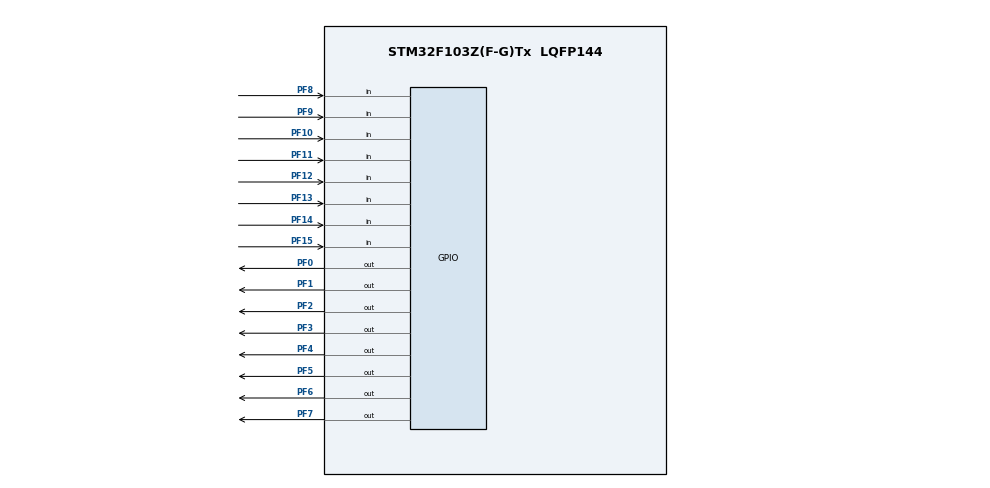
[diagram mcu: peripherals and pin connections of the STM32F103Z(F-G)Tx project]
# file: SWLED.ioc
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Mcu.Family=STM32F1
Mcu.Name=STM32F103Z(F-G)Tx
Mcu.Package=LQFP144
NVIC.PriorityGroup=NVIC_PRIORITYGROUP_4
PA13.Mode=Serial_Wire
PA13.Signal=SYS_JTMS-SWDIO
PA14.Mode=Serial_Wire
PA14.Signal=SYS_JTCK-SWCLK
PF0.Signal=GPIO_Output
PF1.Signal=GPIO_Output
PF10.Signal=GPIO_Input
PF11.Signal=GPIO_Input
PF12.Signal=GPIO_Input
PF13.Signal=GPIO_Input
PF14.Signal=GPIO_Input
PF15.Signal=GPIO_Input
PF2.Signal=GPIO_Output
PF3.Signal=GPIO_Output
PF4.Signal=GPIO_Output
PF5.Signal=GPIO_Output
PF6.Signal=GPIO_Output
PF7.Signal=GPIO_Output
PF8.GPIO_PuPd=GPIO_NOPULL
PF8.Signal=GPIO_Input
PF9.Signal=GPIO_Input
ProjectManager.HeapSize=0x200
ProjectManager.StackSize=0x400
ProjectManager.TargetToolchain=MDK-ARM V5.27
RCC.APB1Freq_Value=8000000
RCC.APB2Freq_Value=8000000
board=custom

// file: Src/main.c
/* USER CODE BEGIN Header */
/**
  ******************************************************************************
  * @file           : main.c
  * @brief          : Main program body
  ******************************************************************************
  * @attention
  *
  * <h2><center>&copy; Copyright (c) 2019 STMicroelectronics.
  * All rights reserved.</center></h2>
  *
  * This software component is licensed by ST under BSD 3-Clause license,
  * the "License"; You may not use this file except in compliance with the
  * License. You may obtain a copy of the License at:
  *                        opensource.org/licenses/BSD-3-Clause
  *
  ******************************************************************************
  */
/* USER CODE END Header */

#include "main.h"

void SystemClock_Config(void);
static void MX_GPIO_Init(void);

int main(void)
{

  /* MCU Configuration--------------------------------------------------------*/

  /* Reset of all peripherals, Initializes the Flash interface and the Systick. */
  HAL_Init();

  /* Configure the system clock */
  SystemClock_Config();

  /* Initialize all configured peripherals */
  MX_GPIO_Init();
  /* USER CODE BEGIN 2 */
	/*
	 * Trun on the LED sequentially.
	 *
	 * Bit Flag
	 * (1 << 0) = 0b0000 0001 = GPIO_PIN_0
	 * (1 << 1) = 0b0000 0010 = GPIO_PIN_1
	 * (1 << 2) = 0b0000 0100 = GPIO_PIN_2
	 * (1 << 3) = 0b0000 1000 = GPIO_PIN_3
	 * (1 << 4) = 0b0001 0000 = GPIO_PIN_4
	 * (1 << 5) = 0b0010 0000 = GPIO_PIN_5
	 * (1 << 6) = 0b0100 0000 = GPIO_PIN_6
	 * (1 << 7) = 0b1000 0000 = GPIO_PIN_7
	 */
	for (int i = 0; i < 8; i++) {
		HAL_GPIO_WritePin(GPIOF, (1 << i), GPIO_PIN_SET);
		HAL_Delay(100);
	}

	/*
	 * Trun off the LED sequentially.
	 */
	for (int i = 0; i < 8; i++) {
		HAL_GPIO_WritePin(GPIOF, (1 << i), GPIO_PIN_RESET);
		HAL_Delay(100);
	}
  /* USER CODE END 2 */

  /* Infinite loop */
  /* USER CODE BEGIN WHILE */
  while (1)
  {
  	for (int i = 0; i < 8; i++) {
  		if (!HAL_GPIO_ReadPin(GPIOF, (1 << (i + 8))))
  			HAL_GPIO_WritePin(GPIOF, (1 << i), GPIO_PIN_SET);
  		else
  			HAL_GPIO_WritePin(GPIOF, (1 << i), GPIO_PIN_RESET);
  	}
    /* USER CODE END WHILE */

  }
}

void SystemClock_Config(void)
{
  RCC_OscInitTypeDef RCC_OscInitStruct = {0};
  RCC_ClkInitTypeDef RCC_ClkInitStruct = {0};

  /** Initializes the CPU, AHB and APB busses clocks
  */
  RCC_OscInitStruct.OscillatorType = RCC_OSCILLATORTYPE_HSI;
  RCC_OscInitStruct.HSIState = RCC_HSI_ON;
  RCC_OscInitStruct.HSICalibrationValue = RCC_HSICALIBRATION_DEFAULT;
  RCC_OscInitStruct.PLL.PLLState = RCC_PLL_NONE;
  if (HAL_RCC_OscConfig(&RCC_OscInitStruct) != HAL_OK)
  {
    Error_Handler();
  }
  /** Initializes the CPU, AHB and APB busses clocks
  */
  RCC_ClkInitStruct.ClockType = RCC_CLOCKTYPE_HCLK|RCC_CLOCKTYPE_SYSCLK
                              |RCC_CLOCKTYPE_PCLK1|RCC_CLOCKTYPE_PCLK2;
  RCC_ClkInitStruct.SYSCLKSource = RCC_SYSCLKSOURCE_HSI;
  RCC_ClkInitStruct.AHBCLKDivider = RCC_SYSCLK_DIV1;
  RCC_ClkInitStruct.APB1CLKDivider = RCC_HCLK_DIV1;
  RCC_ClkInitStruct.APB2CLKDivider = RCC_HCLK_DIV1;

  if (HAL_RCC_ClockConfig(&RCC_ClkInitStruct, FLASH_LATENCY_0) != HAL_OK)
  {
    Error_Handler();
  }
}

static void MX_GPIO_Init(void)
{
  GPIO_InitTypeDef GPIO_InitStruct = {0};

  /* GPIO Ports Clock Enable */
  __HAL_RCC_GPIOF_CLK_ENABLE();
  __HAL_RCC_GPIOA_CLK_ENABLE();

  /*Configure GPIO pin Output Level */
  HAL_GPIO_WritePin(GPIOF, GPIO_PIN_0|GPIO_PIN_1|GPIO_PIN_2|GPIO_PIN_3
                          |GPIO_PIN_4|GPIO_PIN_5|GPIO_PIN_6|GPIO_PIN_7, GPIO_PIN_RESET);

  /*Configure GPIO pins : PF0 PF1 PF2 PF3
                           PF4 PF5 PF6 PF7 */
  GPIO_InitStruct.Pin = GPIO_PIN_0|GPIO_PIN_1|GPIO_PIN_2|GPIO_PIN_3
                          |GPIO_PIN_4|GPIO_PIN_5|GPIO_PIN_6|GPIO_PIN_7;
  GPIO_InitStruct.Mode = GPIO_MODE_OUTPUT_PP;
  GPIO_InitStruct.Pull = GPIO_NOPULL;
  GPIO_InitStruct.Speed = GPIO_SPEED_FREQ_LOW;
  HAL_GPIO_Init(GPIOF, &GPIO_InitStruct);

  /*Configure GPIO pins : PF8 PF9 PF10 PF11
                           PF12 PF13 PF14 PF15 */
  GPIO_InitStruct.Pin = GPIO_PIN_8|GPIO_PIN_9|GPIO_PIN_10|GPIO_PIN_11
                          |GPIO_PIN_12|GPIO_PIN_13|GPIO_PIN_14|GPIO_PIN_15;
  GPIO_InitStruct.Mode = GPIO_MODE_INPUT;
  GPIO_InitStruct.Pull = GPIO_NOPULL;
  HAL_GPIO_Init(GPIOF, &GPIO_InitStruct);

}

void Error_Handler(void)
{
}

/************************ (C) COPYRIGHT STMicroelectronics *****END OF FILE****/
